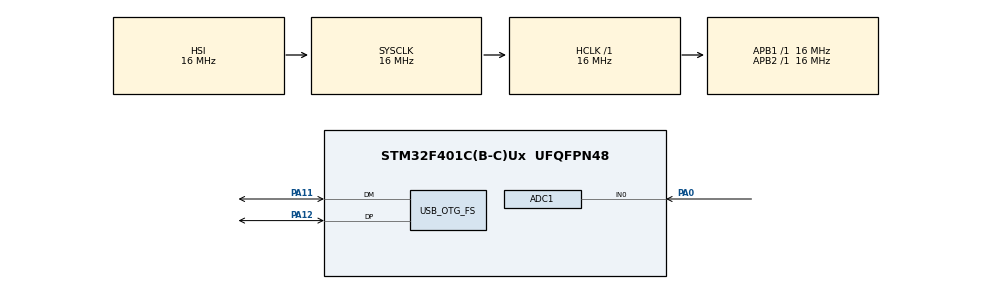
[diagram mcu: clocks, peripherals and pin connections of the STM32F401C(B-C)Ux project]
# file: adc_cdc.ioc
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ADC1.Channel-0\#ChannelRegularConversion=ADC_CHANNEL_0
ADC1.ClockPrescaler=ADC_CLOCK_SYNC_PCLK_DIV2
ADC1.DMAContinuousRequests=ENABLE
ADC1.ExternalTrigConv=ADC_EXTERNALTRIGCONV_T3_TRGO
ADC1.NbrOfConversion=1
ADC1.NbrOfConversionFlag=1
ADC1.Rank-0\#ChannelRegularConversion=1
ADC1.SamplingTime-0\#ChannelRegularConversion=ADC_SAMPLETIME_15CYCLES
ADC1.master=1
Dma.ADC1.0.Direction=DMA_PERIPH_TO_MEMORY
Dma.ADC1.0.FIFOMode=DMA_FIFOMODE_DISABLE
Dma.ADC1.0.Instance=DMA2_Stream0
Dma.ADC1.0.MemDataAlignment=DMA_MDATAALIGN_HALFWORD
Dma.ADC1.0.MemInc=DMA_MINC_ENABLE
Dma.ADC1.0.Mode=DMA_CIRCULAR
Dma.ADC1.0.PeriphDataAlignment=DMA_PDATAALIGN_HALFWORD
Dma.ADC1.0.PeriphInc=DMA_PINC_DISABLE
Dma.ADC1.0.Priority=DMA_PRIORITY_LOW
Dma.Request0=ADC1
Mcu.Family=STM32F4
Mcu.Name=STM32F401C(B-C)Ux
Mcu.Package=UFQFPN48
NVIC.DMA2_Stream0_IRQn=true\:0\:0\:false\:false\:true\:false\:true
NVIC.OTG_FS_IRQn=true\:0\:0\:false\:false\:true\:false\:true
NVIC.PriorityGroup=NVIC_PRIORITYGROUP_4
PA0-WKUP.Signal=ADCx_IN0
PA11.Mode=Device_Only
PA11.Signal=USB_OTG_FS_DM
PA12.Mode=Device_Only
PA12.Signal=USB_OTG_FS_DP
PC14-OSC32_IN.Mode=LSE-External-Oscillator
PC14-OSC32_IN.Signal=RCC_OSC32_IN
PC15-OSC32_OUT.Mode=LSE-External-Oscillator
PC15-OSC32_OUT.Signal=RCC_OSC32_OUT
PH0\ -\ OSC_IN.Mode=HSE-External-Oscillator
PH0\ -\ OSC_IN.Signal=RCC_OSC_IN
PH1\ -\ OSC_OUT.Mode=HSE-External-Oscillator
PH1\ -\ OSC_OUT.Signal=RCC_OSC_OUT
ProjectManager.HeapSize=0x200
ProjectManager.StackSize=0x400
ProjectManager.TargetToolchain=STM32CubeIDE
RCC.48MHZClocksFreq_Value=48000000
RCC.AHBFreq_Value=16000000
RCC.APB1Freq_Value=16000000
RCC.APB2Freq_Value=16000000
RCC.CortexFreq_Value=16000000
RCC.HSE_VALUE=25000000
RCC.HSI_VALUE=16000000
RCC.PLLM=15
RCC.PLLN=144
RCC.PLLQ=5
RCC.SYSCLKFreq_VALUE=16000000
RCC.VCOOutputFreq_Value=240000000
SH.ADCx_IN0.0=ADC1_IN0,IN0
TIM3.Channel-Output\ Compare4\ No\ Output=TIM_CHANNEL_4
TIM3.Period=10-1
TIM3.Prescaler=16-1
TIM3.TIM_MasterOutputTrigger=TIM_TRGO_UPDATE
USB_DEVICE.CLASS_NAME_FS=CDC
USB_DEVICE.VirtualMode=Cdc
USB_DEVICE.VirtualModeFS=Cdc_FS
USB_OTG_FS.VirtualMode=Device_Only
VP_TIM3_VS_ClockSourceINT.Mode=Internal
VP_TIM3_VS_no_output4.Mode=Output Compare4 No Output
VP_USB_DEVICE_VS_USB_DEVICE_CDC_FS.Mode=CDC_FS
board=custom

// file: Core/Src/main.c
/* USER CODE BEGIN Header */
/**
 ******************************************************************************
 * @file           : main.c
 * @brief          : Main program body
 ******************************************************************************
 * @attention
 *
 * <h2><center>&copy; Copyright (c) 2021 STMicroelectronics.
 * All rights reserved.</center></h2>
 *
 * This software component is licensed by ST under BSD 3-Clause license,
 * the "License"; You may not use this file except in compliance with the
 * License. You may obtain a copy of the License at:
 *                        opensource.org/licenses/BSD-3-Clause
 *
 ******************************************************************************
 */
/* USER CODE END Header */
#include "main.h"
#include "usb_device.h"

/* USER CODE BEGIN Includes */
#include "usbd_cdc_if.h" // Plik bedacy interfejsem uzytkownika do kontrolera USB
/* USER CODE END Includes */

ADC_HandleTypeDef hadc1;
DMA_HandleTypeDef hdma_adc1;

TIM_HandleTypeDef htim3;

/* USER CODE BEGIN PV */
#define ADC_BUFFER_SIZE 4096
#define ADC_HALF_BUFFER_SIZE 2048
//volatile uint16_t adc_buffer;
uint16_t ADCValues[ADC_BUFFER_SIZE];
uint16_t CDCBuffer[ADC_BUFFER_SIZE];
//uint16_t MessageLength;
//char combined[2048];
//uint i = 0;
//char buffer[8];
//volatile uint8_t toggle = 0;
/* USER CODE END PV */

void SystemClock_Config(void);
static void MX_GPIO_Init(void);
static void MX_DMA_Init(void);
static void MX_ADC1_Init(void);
static void MX_TIM3_Init(void);

int main(void)
{

  /* MCU Configuration--------------------------------------------------------*/

  /* Reset of all peripherals, Initializes the Flash interface and the Systick. */
  HAL_Init();

  /* Configure the system clock */
  SystemClock_Config();

  /* Initialize all configured peripherals */
  MX_GPIO_Init();
  MX_DMA_Init();
  MX_ADC1_Init();
  MX_USB_DEVICE_Init();
  MX_TIM3_Init();
  /* USER CODE BEGIN 2 */
	HAL_Delay(4000);
//  HAL_ADC_Start_IT(&hadc1);
//  HAL_ADC_Start_DMA(&hadc1, (uint32_t)ADCBuffer, 1);
//	HAL_ADC_Start(&hadc1);
//	HAL_ADC_Start_DMA(&hadc1, (uint32_t*) &adc_buffer, 1);
	HAL_ADC_Start_DMA(&hadc1, ADCValues, ADC_BUFFER_SIZE);
	HAL_TIM_Base_Start_IT(&htim3);
  /* USER CODE END 2 */

  /* Infinite loop */
	while (1) {

    /* USER CODE BEGIN 3 */
//		if (HAL_ADC_PollForConversion(&hadc1, 10) == HAL_OK) {
//			MessageLength = snprintf(buffer, sizeof(buffer), "%6d\n",
//					HAL_ADC_GetValue(&hadc1));
//			CDC_Transmit_FS(buffer, 7);
//			HAL_ADC_Start(&hadc1);
//
//		}
	}
  /* USER CODE END 3 */
}

void SystemClock_Config(void)
{
  RCC_OscInitTypeDef RCC_OscInitStruct = {0};
  RCC_ClkInitTypeDef RCC_ClkInitStruct = {0};

  /** Configure the main internal regulator output voltage
  */
  __HAL_RCC_PWR_CLK_ENABLE();
  __HAL_PWR_VOLTAGESCALING_CONFIG(PWR_REGULATOR_VOLTAGE_SCALE2);
  /** Initializes the RCC Oscillators according to the specified parameters
  * in the RCC_OscInitTypeDef structure.
  */
  RCC_OscInitStruct.OscillatorType = RCC_OSCILLATORTYPE_HSI|RCC_OSCILLATORTYPE_HSE;
  RCC_OscInitStruct.HSEState = RCC_HSE_ON;
  RCC_OscInitStruct.HSIState = RCC_HSI_ON;
  RCC_OscInitStruct.HSICalibrationValue = RCC_HSICALIBRATION_DEFAULT;
  RCC_OscInitStruct.PLL.PLLState = RCC_PLL_ON;
  RCC_OscInitStruct.PLL.PLLSource = RCC_PLLSOURCE_HSE;
  RCC_OscInitStruct.PLL.PLLM = 15;
  RCC_OscInitStruct.PLL.PLLN = 144;
  RCC_OscInitStruct.PLL.PLLP = RCC_PLLP_DIV2;
  RCC_OscInitStruct.PLL.PLLQ = 5;
  if (HAL_RCC_OscConfig(&RCC_OscInitStruct) != HAL_OK)
  {
    Error_Handler();
  }
  /** Initializes the CPU, AHB and APB buses clocks
  */
  RCC_ClkInitStruct.ClockType = RCC_CLOCKTYPE_HCLK|RCC_CLOCKTYPE_SYSCLK
                              |RCC_CLOCKTYPE_PCLK1|RCC_CLOCKTYPE_PCLK2;
  RCC_ClkInitStruct.SYSCLKSource = RCC_SYSCLKSOURCE_HSI;
  RCC_ClkInitStruct.AHBCLKDivider = RCC_SYSCLK_DIV1;
  RCC_ClkInitStruct.APB1CLKDivider = RCC_HCLK_DIV1;
  RCC_ClkInitStruct.APB2CLKDivider = RCC_HCLK_DIV1;

  if (HAL_RCC_ClockConfig(&RCC_ClkInitStruct, FLASH_LATENCY_0) != HAL_OK)
  {
    Error_Handler();
  }
}

static void MX_ADC1_Init(void)
{

  ADC_ChannelConfTypeDef sConfig = {0};

  /** Configure the global features of the ADC (Clock, Resolution, Data Alignment and number of conversion)
  */
  hadc1.Instance = ADC1;
  hadc1.Init.ClockPrescaler = ADC_CLOCK_SYNC_PCLK_DIV2;
  hadc1.Init.Resolution = ADC_RESOLUTION_12B;
  hadc1.Init.ScanConvMode = DISABLE;
  hadc1.Init.ContinuousConvMode = DISABLE;
  hadc1.Init.DiscontinuousConvMode = DISABLE;
  hadc1.Init.ExternalTrigConvEdge = ADC_EXTERNALTRIGCONVEDGE_RISING;
  hadc1.Init.ExternalTrigConv = ADC_EXTERNALTRIGCONV_T3_TRGO;
  hadc1.Init.DataAlign = ADC_DATAALIGN_RIGHT;
  hadc1.Init.NbrOfConversion = 1;
  hadc1.Init.DMAContinuousRequests = ENABLE;
  hadc1.Init.EOCSelection = ADC_EOC_SINGLE_CONV;
  if (HAL_ADC_Init(&hadc1) != HAL_OK)
  {
    Error_Handler();
  }
  /** Configure for the selected ADC regular channel its corresponding rank in the sequencer and its sample time.
  */
  sConfig.Channel = ADC_CHANNEL_0;
  sConfig.Rank = 1;
  sConfig.SamplingTime = ADC_SAMPLETIME_15CYCLES;
  if (HAL_ADC_ConfigChannel(&hadc1, &sConfig) != HAL_OK)
  {
    Error_Handler();
  }

}

static void MX_TIM3_Init(void)
{

  TIM_ClockConfigTypeDef sClockSourceConfig = {0};
  TIM_MasterConfigTypeDef sMasterConfig = {0};
  TIM_OC_InitTypeDef sConfigOC = {0};

  htim3.Instance = TIM3;
  htim3.Init.Prescaler = 16-1;
  htim3.Init.CounterMode = TIM_COUNTERMODE_UP;
  htim3.Init.Period = 10-1;
  htim3.Init.ClockDivision = TIM_CLOCKDIVISION_DIV1;
  htim3.Init.AutoReloadPreload = TIM_AUTORELOAD_PRELOAD_DISABLE;
  if (HAL_TIM_Base_Init(&htim3) != HAL_OK)
  {
    Error_Handler();
  }
  sClockSourceConfig.ClockSource = TIM_CLOCKSOURCE_INTERNAL;
  if (HAL_TIM_ConfigClockSource(&htim3, &sClockSourceConfig) != HAL_OK)
  {
    Error_Handler();
  }
  if (HAL_TIM_OC_Init(&htim3) != HAL_OK)
  {
    Error_Handler();
  }
  sMasterConfig.MasterOutputTrigger = TIM_TRGO_UPDATE;
  sMasterConfig.MasterSlaveMode = TIM_MASTERSLAVEMODE_DISABLE;
  if (HAL_TIMEx_MasterConfigSynchronization(&htim3, &sMasterConfig) != HAL_OK)
  {
    Error_Handler();
  }
  sConfigOC.OCMode = TIM_OCMODE_TIMING;
  sConfigOC.Pulse = 0;
  sConfigOC.OCPolarity = TIM_OCPOLARITY_HIGH;
  sConfigOC.OCFastMode = TIM_OCFAST_DISABLE;
  if (HAL_TIM_OC_ConfigChannel(&htim3, &sConfigOC, TIM_CHANNEL_4) != HAL_OK)
  {
    Error_Handler();
  }

}

static void MX_DMA_Init(void)
{

  /* DMA controller clock enable */
  __HAL_RCC_DMA2_CLK_ENABLE();

  /* DMA interrupt init */
  /* DMA2_Stream0_IRQn interrupt configuration */
  HAL_NVIC_SetPriority(DMA2_Stream0_IRQn, 0, 0);
  HAL_NVIC_EnableIRQ(DMA2_Stream0_IRQn);

}

static void MX_GPIO_Init(void)
{

  /* GPIO Ports Clock Enable */
  __HAL_RCC_GPIOC_CLK_ENABLE();
  __HAL_RCC_GPIOH_CLK_ENABLE();
  __HAL_RCC_GPIOA_CLK_ENABLE();

}

/* USER CODE BEGIN 4 */
void HAL_ADC_ConvCpltCallback(ADC_HandleTypeDef *hadc1) {
//	uint16_t i;
//	toggle = !toggle;
	for (int i = ADC_HALF_BUFFER_SIZE; i < ADC_BUFFER_SIZE; ++i) {
//		if (toggle)
			CDCBuffer[i] = ADCValues[i];
	}
//	CDCBuffer[2024] = "\n";
	//while(
			CDC_Transmit_FS(CDCBuffer, ADC_BUFFER_SIZE);// != USBD_OK){

	//}
//	CDC_Transmit_FS(CDCBuffer, ADC_BUFFER_SIZE);
//	strcpy(combined, ADCValues);
//	CDC_Transmit_FS(ADCValues, sizeof(ADCValues));
//	HAL_Delay(1);
//	HAL_ADC_Start_DMA(hadc1, ADCValues,	ADC_BUFFER_SIZE);
//	MessageLength = snprintf(buffer, sizeof(buffer), "%6d\n", adc_buffer);
//	CDC_Transmit_FS(buffer, 7);
}

void HAL_ADC_ConvHalfCpltCallback(ADC_HandleTypeDef *hadc1){
	for (int i = 0; i < ADC_HALF_BUFFER_SIZE; ++i) {
		CDCBuffer[i] = ADCValues[i];
	}
}
/* USER CODE END 4 */

void Error_Handler(void)
{
	__disable_irq();
	while (1) {
	}
}

/************************ (C) COPYRIGHT STMicroelectronics *****END OF FILE****/
